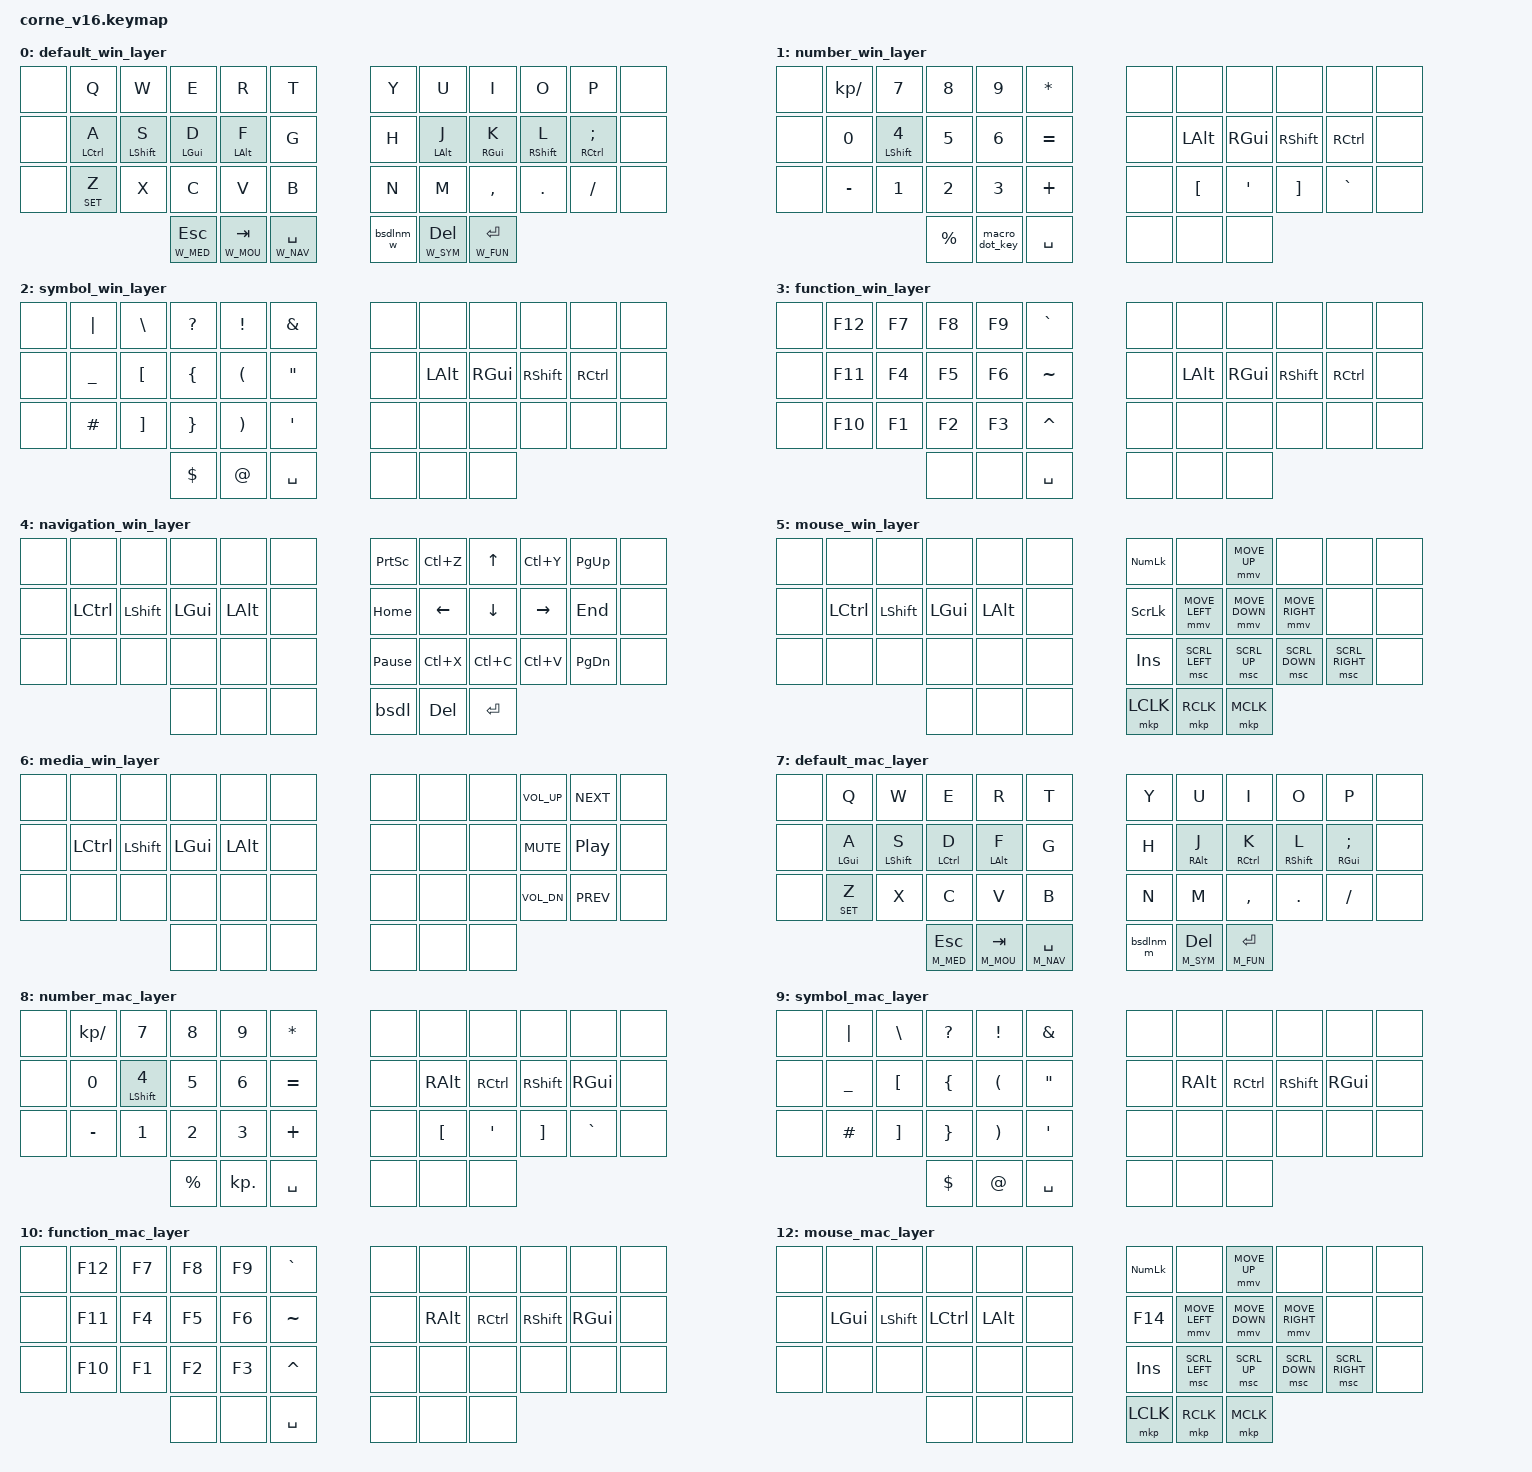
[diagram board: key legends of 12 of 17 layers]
#include <behaviors.dtsi>
#include <dt-bindings/zmk/keys.h>
#include <dt-bindings/zmk/bt.h>
#include <dt-bindings/zmk/outputs.h>
#include <dt-bindings/zmk/mouse.h>

#define W_DEF     0
#define W_NUM     1
#define W_SYM     2
#define W_FUN     3
#define W_NAV     4
#define W_MOU     5
#define W_MED     6

#define M_DEF     7
#define M_NUM     8
#define M_SYM     9
#define M_FUN     10
#define M_NAV     11
#define M_MOU     12
#define M_MED     13

#define CS1       14
#define CS2       15

#define SET       16

&lt {
	flavor = "hold-preferred";
	tapping-term-ms = <300>;
	quick-tap-ms = <300>;
	// global-quick-tap;
};

/ {
	behaviors {
		ht: hold_tap_kp_kp {
			label = "hold_tap";
			compatible = "zmk,behavior-hold-tap";
			#binding-cells = <2>;
			flavor = "balanced";
			// flavor = "hold-preferred";
			tapping-term-ms = <250>;
			quick-tap-ms = <250>;
			// global-quick-tap;
			bindings = <&kp>, <&kp>;
		};
		bsdl: bcksp_del {
            		compatible = "zmk,behavior-mod-morph";
            		#binding-cells = <0>;
            		bindings = <&kp BSPC>, <&kp DEL>;
            		mods = <(MOD_LSFT|MOD_RSFT)>;
        	};
		bsdlnm_w: bcksp_del_num_w {
            		compatible = "zmk,behavior-mod-morph";
            		#binding-cells = <0>;
            		bindings = <&lt W_NUM BSPC>, <&lt W_NUM DEL>;
            		mods = <(MOD_LSFT|MOD_RSFT)>;
        	};
		bsdlnm_m: bcksp_del_num_m {
            		compatible = "zmk,behavior-mod-morph";
            		#binding-cells = <0>;
            		bindings = <&lt M_NUM BSPC>, <&lt M_NUM DEL>;
            		mods = <(MOD_LSFT|MOD_RSFT)>;
        	};	};

	macros {
		macro_dot_key: macro_dot_key {
			compatible = "zmk,behavior-macro";
			#binding-cells = <0>;
			wait-ms = <40>;
			tap-ms = <40>;
			bindings
				= <&kp KP_NUM>
				, <&kp KP_DOT>
				, <&kp CLEAR2>
				;
		};
	};

        keymap {
                compatible = "zmk,keymap";

                default_win_layer {
                        bindings = <
//╭───────┬───────────────┬───────────────┬───────────────┬───────────────┬───────────────╮   ╭───────────────┬───────────────┬───────────────┬───────────────┬───────────────┬───────╮
//│       │ Q             │ W             │ E             │ R             │ T             │   │ Y             │ U             │ I             │ O             │ P             │       │
    &none   &kp Q           &kp W           &kp E           &kp R           &kp T               &kp Y           &kp U           &kp I           &kp O           &kp P           &none
//├───────┼───────────────┼───────────────┼───────────────┼───────────────┼───────────────┤   ├───────────────┼───────────────┼───────────────┼───────────────┼───────────────┼───────┤
//│       │ A(CTRL)       │ S(SHIFT)      │ D(GUI)        │ F(ALT)        │ G             │   │ H             │ J(ALT)        │ K(GUI)        │ L(SHIFT)      │ ;(CTRL)       │       │
    &none   &ht LCTRL A     &ht LSHFT S     &ht LGUI D      &ht LALT F      &kp G               &kp H           &ht LALT J      &ht RGUI K      &ht RSHFT L     &ht RCTRL SEMI  &none
//├───────┼───────────────┼───────────────┼───────────────┼───────────────┼───────────────┤   ├───────────────┼───────────────┼───────────────┼───────────────┼───────────────┼───────┤
//│       │ Z(MO SET)     │ X             │ C             │ V             │ B             │   │ N             │ M             │ ,             │ .             │ /             │       │
    &none   &lt SET Z       &kp X           &kp C           &kp V           &kp B               &kp N           &kp M           &kp COMMA       &kp DOT         &kp FSLH        &none
//╰───────┴───────────────┴───────────────┼───────────────┼───────────────┼───────────────┤   ├───────────────┼───────────────┼───────────────┼───────────────┴───────────────┴───────╯
//                                        │ ESC(MO MED)   │ TAB(MO MOU)   │ SPACE(MO NAV) │   │ BKSPDL(MO NUM)│ DEL(MO SYM)   │ ENTER(MO FUN) │
                                            &lt W_MED ESC   &lt W_MOU TAB   &lt W_NAV SPACE     &bsdlnm_w       &lt W_SYM DEL   &lt W_FUN RET
//                                        ╰───────────────┴───────────────┴───────────────╯   ╰───────────────┴───────────────┴───────────────╯
                        >;
                };
                number_win_layer {
                        bindings = <
//╭───────┬───────────────┬───────────────┬───────────────┬───────────────┬───────────────╮   ╭───────────────┬───────────────┬───────────────┬───────────────┬───────────────┬───────╮
//│       │ /             │ 7             │ 8             │ 9             │ *             │   │               │               │               │               │               │       │
    &none   &kp KP_DIVIDE   &kp N7          &kp N8          &kp N9          &kp STAR            &none           &none           &none           &none           &none           &none
//├───────┼───────────────┼───────────────┼───────────────┼───────────────┼───────────────┤   ├───────────────┼───────────────┼───────────────┼───────────────┼───────────────┼───────┤
//│       │ 0             │ 4(SHIFT)      │ 5             │ 6             │ =             │   │               │ ALT           │ GUI           │ SHIFT         │ CTRL          │       │
    &none   &kp N0          &ht LSHFT N4    &kp N5          &kp N6          &kp EQUAL           &none           &kp LALT        &kp RGUI        &kp RSHFT       &kp RCTRL       &none
//├───────┼───────────────┼───────────────┼───────────────┼───────────────┼───────────────┤   ├───────────────┼───────────────┼───────────────┼───────────────┼───────────────┼───────┤
//│       │ -             │ 1             │ 2             │ 3             │ +             │   │               │ Х             │ Э             │ Ъ             │ Ё             │       │
    &none   &kp MINUS       &kp N1          &kp N2          &kp N3          &kp PLUS            &none           &kp LBKT        &kp SQT         &kp RBKT        &kp GRAVE       &none
//╰───────┴───────────────┴───────────────┼───────────────┼───────────────┼───────────────┤   ├───────────────┼───────────────┼───────────────┼───────────────┴───────────────┴───────╯
//                                        │ %             │ .             │ SPACE         │   │               │               │               │
                                            &kp PRCNT       &macro_dot_key  &kp SPACE           &none           &none           &none
//                                        ╰───────────────┴───────────────┴───────────────╯   ╰───────────────┴───────────────┴───────────────╯
                        >;
                };
                symbol_win_layer {
                        bindings = <
//╭───────┬───────────────┬───────────────┬───────────────┬───────────────┬───────────────╮   ╭───────────────┬───────────────┬───────────────┬───────────────┬───────────────┬───────╮
//│       │ |             │ \             │ ?             │ !             │ &             │   │               │               │               │               │               │       │
    &none   &kp PIPE        &kp BSLH        &kp QMARK       &kp EXCL        &kp AMPS            &none           &none           &none           &none           &none           &none
//├───────┼───────────────┼───────────────┼───────────────┼───────────────┼───────────────┤   ├───────────────┼───────────────┼───────────────┼───────────────┼───────────────┼───────┤
//│       │ _             │ [             │ {             │ (             │ "             │   │               │ ALT           │ GUI           │ SHIFT         │ CTRL          │       │
    &none   &kp UNDER       &kp LBKT        &kp LBRC        &kp LPAR        &kp DQT             &none           &kp LALT        &kp RGUI        &kp RSHFT       &kp RCTRL       &none
//├───────┼───────────────┼───────────────┼───────────────┼───────────────┼───────────────┤   ├───────────────┼───────────────┼───────────────┼───────────────┼───────────────┼───────┤
//│       │ #             │ ]             │ }             │ )             │ '             │   │               │               │               │               │               │       │
    &none   &kp HASH        &kp RBKT        &kp RBRC        &kp RPAR        &kp SQT             &none           &none           &none           &none           &none           &none
//╰───────┴───────────────┴───────────────┼───────────────┼───────────────┼───────────────┤   ├───────────────┼───────────────┼───────────────┼───────────────┴───────────────┴───────╯
//                                        │ $             │ @             │ SPACE         │   │               │               │               │
                                            &kp DLLR        &kp AT          &kp SPACE           &none           &none           &none
//                                        ╰───────────────┴───────────────┴───────────────╯   ╰───────────────┴───────────────┴───────────────╯
                        >;
                };
                function_win_layer {
                        bindings = <
//╭───────┬───────────────┬───────────────┬───────────────┬───────────────┬───────────────╮   ╭───────────────┬───────────────┬───────────────┬───────────────┬───────────────┬───────╮
//│       │ F12           │ F7            │ F8            │ F9            │ `             │   │               │               │               │               │               │       │
    &none   &kp F12         &kp F7          &kp F8          &kp F9          &kp GRAVE           &none           &none           &none           &none           &none           &none
//├───────┼───────────────┼───────────────┼───────────────┼───────────────┼───────────────┤   ├───────────────┼───────────────┼───────────────┼───────────────┼───────────────┼───────┤
//│       │ F11           │ F4            │ F5            │ F6            │ ~             │   │               │ ALT           │ GUI           │ SHIFT         │ CTRL          │       │
    &none   &kp F11         &kp F4          &kp F5          &kp F6          &kp TILDE           &none           &kp LALT        &kp RGUI        &kp RSHFT       &kp RCTRL       &none
//├───────┼───────────────┼───────────────┼───────────────┼───────────────┼───────────────┤   ├───────────────┼───────────────┼───────────────┼───────────────┼───────────────┼───────┤
//│       │ F10           │ F1            │ F2            │ F3            │ ^             │   │               │               │               │               │               │       │
    &none   &kp F10         &kp F1          &kp F2          &kp F3          &kp CARET           &none           &none           &none           &none           &none           &none
//╰───────┴───────────────┴───────────────┼───────────────┼───────────────┼───────────────┤   ├───────────────┼───────────────┼───────────────┼───────────────┴───────────────┴───────╯
//                                        │               │               │ SPACE         │   │               │               │               │   
                                            &none           &none           &kp SPACE           &none           &none           &none
//                                        ╰───────────────┴───────────────┴───────────────╯   ╰───────────────┴───────────────┴───────────────╯
                        >;
                };
                navigation_win_layer {
                        bindings = <
//╭───────┬───────────────┬───────────────┬───────────────┬───────────────┬───────────────╮   ╭───────────────┬───────────────┬───────────────┬───────────────┬───────────────┬───────╮
//│       │               │               │               │               │               │   │ PrtScr        │ Undo          │ Up            │ Redo          │ PGUP          │       │
    &none   &none           &none           &none           &none           &none               &kp PSCRN       &kp LC(Z)       &kp UP          &kp LC(Y)       &kp PG_UP       &none
//├───────┼───────────────┼───────────────┼───────────────┼───────────────┼───────────────┤   ├───────────────┼───────────────┼───────────────┼───────────────┼───────────────┼───────┤
//│       │ CTRL          │ SHIFT         │ GUI           │ ALT           │               │   │ HOME          │ Left          │ Down          │ Right         │ END           │       │
    &none   &kp LCTRL       &kp LSHFT       &kp LGUI        &kp LALT        &none               &kp HOME        &kp LEFT        &kp DOWN        &kp RIGHT       &kp END         &none
//├───────┼───────────────┼───────────────┼───────────────┼───────────────┼───────────────┤   ├───────────────┼───────────────┼───────────────┼───────────────┼───────────────┼───────┤
//│       │               │               │               │               │               │   │ Pause         │ Cut           │ Copy          │ Paste         │ PGDN          │       │
    &none   &none           &none           &none           &none           &none               &kp PAUSE_BREAK &kp LC(X)       &kp LC(C)       &kp LC(V)       &kp PG_DN       &none
//╰───────┴───────────────┴───────────────┼───────────────┼───────────────┼───────────────┤   ├───────────────┼───────────────┼───────────────┼───────────────┴───────────────┴───────╯
//                                        │               │               │               │   │ BKSP_DEL      │ DEL           │ ENTER         │
                                            &none           &none           &none               &bsdl           &kp DEL         &kp RET
//                                        ╰───────────────┴───────────────┴───────────────╯   ╰───────────────┴───────────────┴───────────────╯
                        >;
                };
                mouse_win_layer {
                        bindings = <
//╭───────┬───────────────┬───────────────┬───────────────┬───────────────┬───────────────╮   ╭───────────────┬───────────────┬───────────────┬───────────────┬───────────────┬───────╮
//│       │               │               │               │               │               │   │ NumLock       │               │ MS Up         │               │               │       │
    &none   &none           &none           &none           &none           &none               &kp KP_NUM      &none           &mmv MOVE_UP    &none           &none           &none
//├───────┼───────────────┼───────────────┼───────────────┼───────────────┼───────────────┤   ├───────────────┼───────────────┼───────────────┼───────────────┼───────────────┼───────┤
//│       │ CTRL          │ SHIFT         │ GUI           │ ALT           │               │   │ ScrLock       │ MS Left       │ MS Down       │ MS Right      │               │       │
    &none   &kp LCTRL       &kp LSHFT       &kp LGUI        &kp LALT        &none               &kp SLCK        &mmv MOVE_LEFT  &mmv MOVE_DOWN &mmv MOVE_RIGHT  &none           &none
//├───────┼───────────────┼───────────────┼───────────────┼───────────────┼───────────────┤   ├───────────────┼───────────────┼───────────────┼───────────────┼───────────────┼───────┤
//│       │               │               │               │               │               │   │ Insert        │ SC Left       │ SC Up         │ SC Down       │ SC Right      │       │
    &none   &none           &none           &none           &none           &none               &kp INS         &msc SCRL_LEFT  &msc SCRL_UP    &msc SCRL_DOWN  &msc SCRL_RIGHT &none
//╰───────┴───────────────┴───────────────┼───────────────┼───────────────┼───────────────┤   ├───────────────┼───────────────┼───────────────┼───────────────┴───────────────┴───────╯
//                                        │               │               │               │   │ MS_BT_Left    │ MS_BT_Right   │ MS_BT_Middle  │
                                            &none           &none           &none               &mkp LCLK       &mkp RCLK       &mkp MCLK
//                                        ╰───────────────┴───────────────┴───────────────╯   ╰───────────────┴───────────────┴───────────────╯
                        >;
                };
                media_win_layer {
                        bindings = <
//╭───────┬───────────────┬───────────────┬───────────────┬───────────────┬───────────────╮   ╭───────────────┬───────────────┬───────────────┬───────────────┬───────────────┬───────╮
//│       │               │               │               │               │               │   │               │               │               │ Volume Up     │ Skip Forward  │       │
    &none   &none           &none           &none           &none           &none               &none           &none           &none           &kp C_VOL_UP    &kp C_NEXT      &none
//├───────┼───────────────┼───────────────┼───────────────┼───────────────┼───────────────┤   ├───────────────┼───────────────┼───────────────┼───────────────┼───────────────┼───────┤
//│       │ CTRL          │ SHIFT         │ GUI           │ ALT           │               │   │               │               │               │ Mute          │ Play Paus     │       │
    &none   &kp LCTRL       &kp LSHFT       &kp LGUI        &kp LALT        &none               &none           &none           &none           &kp C_MUTE      &kp C_PP        &none
//├───────┼───────────────┼───────────────┼───────────────┼───────────────┼───────────────┤   ├───────────────┼───────────────┼───────────────┼───────────────┼───────────────┼───────┤
//│       │               │               │               │               │               │   │               │               │               │ Volume Down   │ Skip Back     │       │
    &none   &none           &none           &none           &none           &none               &none           &none           &none           &kp C_VOL_DN    &kp C_PREV      &none
//╰───────┴───────────────┴───────────────┼───────────────┼───────────────┼───────────────┤   ├───────────────┼───────────────┼───────────────┼───────────────┴───────────────┴───────╯
//                                        │               │               │               │   │               │               │               │
                                            &none           &none           &none               &none           &none           &none
//                                        ╰───────────────┴───────────────┴───────────────╯   ╰───────────────┴───────────────┴───────────────╯
                        >;
                };
		default_mac_layer {
                        bindings = <
//╭───────┬───────────────┬───────────────┬───────────────┬───────────────┬───────────────╮   ╭───────────────┬───────────────┬───────────────┬───────────────┬───────────────┬───────╮
//│       │ Q             │ W             │ E             │ R             │ T             │   │ Y             │ U             │ I             │ O             │ P             │       │
    &none   &kp Q           &kp W           &kp E           &kp R           &kp T               &kp Y           &kp U           &kp I           &kp O           &kp P           &none
//├───────┼───────────────┼───────────────┼───────────────┼───────────────┼───────────────┤   ├───────────────┼───────────────┼───────────────┼───────────────┼───────────────┼───────┤
//│       │ A(GUI)        │ S(SHIFT)      │ D(CTRL)       │ F(ALT)        │ G             │   │ H             │ J(ALT)        │ K(CTRL)       │ L(SHIFT)      │ ;(GUI)        │       │
    &none   &ht LGUI A      &ht LSHFT S     &ht LCTRL D     &ht LALT F      &kp G               &kp H           &ht RALT J      &ht RCTRL K     &ht RSHFT L     &ht RGUI SEMI   &none
//├───────┼───────────────┼───────────────┼───────────────┼───────────────┼───────────────┤   ├───────────────┼───────────────┼───────────────┼───────────────┼───────────────┼───────┤
//│       │ Z(MO SET)     │ X             │ C             │ V             │ B             │   │ N             │ M             │ ,             │ .             │ /             │       │
    &none   &lt SET Z       &kp X           &kp C           &kp V           &kp B               &kp N           &kp M           &kp COMMA       &kp DOT         &kp FSLH        &none
//╰───────┴───────────────┴───────────────┼───────────────┼───────────────┼───────────────┤   ├───────────────┼───────────────┼───────────────┼───────────────┴───────────────┴───────╯
//                                        │ ESC(MO MED)   │ TAB(MO MOU)   │ SPACE(MO NAV) │   │ BKSPDL(MO NUM)│ DEL(MO SYM)   │ ENTER(MO FUN) │
                                            &lt M_MED ESC   &lt M_MOU TAB   &lt M_NAV SPACE     &bsdlnm_m       &lt M_SYM DEL   &lt M_FUN RET
//                                        ╰───────────────┴───────────────┴───────────────╯   ╰───────────────┴───────────────┴───────────────╯
                        >;
                };
                number_mac_layer {
                        bindings = <
//╭───────┬───────────────┬───────────────┬───────────────┬───────────────┬───────────────╮   ╭───────────────┬───────────────┬───────────────┬───────────────┬───────────────┬───────╮
//│       │ +             │ 7             │ 8             │ 9             │ *             │   │               │               │               │               │               │       │
    &none   &kp KP_DIVIDE   &kp N7          &kp N8          &kp N9          &kp STAR            &none           &none           &none           &none           &none           &none
//├───────┼───────────────┼───────────────┼───────────────┼───────────────┼───────────────┤   ├───────────────┼───────────────┼───────────────┼───────────────┼───────────────┼───────┤
//│       │ 0             │ 4(SHIFT)      │ 5             │ 6             │ =             │   │               │ ALT           │ CTRL          │ SHIFT         │ GUI           │       │
    &none   &kp N0          &ht LSHFT N4    &kp N5          &kp N6          &kp EQUAL           &none           &kp RALT        &kp RCTRL       &kp RSHFT       &kp RGUI        &none
//├───────┼───────────────┼───────────────┼───────────────┼───────────────┼───────────────┤   ├───────────────┼───────────────┼───────────────┼───────────────┼───────────────┼───────┤
//│       │ -             │ 1             │ 2             │ 3             │ /             │   │               │ Х             │ Э             │ Ъ             │ Ё             │       │
    &none   &kp MINUS       &kp N1          &kp N2          &kp N3          &kp PLUS            &none           &kp LBKT        &kp SQT         &kp RBKT        &kp GRAVE       &none
//╰───────┴───────────────┴───────────────┼───────────────┼───────────────┼───────────────┤   ├───────────────┼───────────────┼───────────────┼───────────────┴───────────────┴───────╯
//                                        │ %             │ .             │ SPACE         │   │               │               │               │
                                            &kp PRCNT       &kp KP_DOT      &kp SPACE           &none           &none           &none
//                                        ╰───────────────┴───────────────┴───────────────╯   ╰───────────────┴───────────────┴───────────────╯
                        >;
                };
                symbol_mac_layer {
                        bindings = <
//╭───────┬───────────────┬───────────────┬───────────────┬───────────────┬───────────────╮   ╭───────────────┬───────────────┬───────────────┬───────────────┬───────────────┬───────╮
//│       │ |             │ \             │ ?             │ !             │ &             │   │               │               │               │               │               │       │
    &none   &kp PIPE        &kp BSLH        &kp QMARK       &kp EXCL        &kp AMPS            &none           &none           &none           &none           &none           &none
//├───────┼───────────────┼───────────────┼───────────────┼───────────────┼───────────────┤   ├───────────────┼───────────────┼───────────────┼───────────────┼───────────────┼───────┤
//│       │ _             │ [             │ {             │ (             │ "             │   │               │ ALT           │ CTRL          │ SHIFT         │ GUI           │       │
    &none   &kp UNDER       &kp LBKT        &kp LBRC        &kp LPAR        &kp DQT             &none           &kp RALT        &kp RCTRL       &kp RSHFT       &kp RGUI        &none
//├───────┼───────────────┼───────────────┼───────────────┼───────────────┼───────────────┤   ├───────────────┼───────────────┼───────────────┼───────────────┼───────────────┼───────┤
//│       │ #             │ ]             │ }             │ )             │ '             │   │               │               │               │               │               │       │
    &none   &kp HASH        &kp RBKT        &kp RBRC        &kp RPAR        &kp SQT             &none           &none           &none           &none           &none           &none
//╰───────┴───────────────┴───────────────┼───────────────┼───────────────┼───────────────┤   ├───────────────┼───────────────┼───────────────┼───────────────┴───────────────┴───────╯
//                                        │ $             │ @             │ SPACE         │   │               │               │               │
                                            &kp DLLR        &kp AT          &kp SPACE           &none           &none           &none
//                                        ╰───────────────┴───────────────┴───────────────╯   ╰───────────────┴───────────────┴───────────────╯
                        >;
                };
                function_mac_layer {
                        bindings = <
//╭───────┬───────────────┬───────────────┬───────────────┬───────────────┬───────────────╮   ╭───────────────┬───────────────┬───────────────┬───────────────┬───────────────┬───────╮
//│       │ F12           │ F7            │ F8            │ F9            │ `             │   │               │               │               │               │               │       │
    &none   &kp F12         &kp F7          &kp F8          &kp F9          &kp GRAVE           &none           &none           &none           &none           &none           &none
//├───────┼───────────────┼───────────────┼───────────────┼───────────────┼───────────────┤   ├───────────────┼───────────────┼───────────────┼───────────────┼───────────────┼───────┤
//│       │ F11           │ F4            │ F5            │ F6            │ ~             │   │               │ ALT           │ CTRL          │ SHIFT         │ GUI           │       │
    &none   &kp F11         &kp F4          &kp F5          &kp F6          &kp TILDE           &none           &kp RALT        &kp RCTRL       &kp RSHFT       &kp RGUI        &none
//├───────┼───────────────┼───────────────┼───────────────┼───────────────┼───────────────┤   ├───────────────┼───────────────┼───────────────┼───────────────┼───────────────┼───────┤
//│       │ F10           │ F1            │ F2            │ F3            │ ^             │   │               │               │               │               │               │       │
    &none   &kp F10         &kp F1          &kp F2          &kp F3          &kp CARET           &none           &none           &none           &none           &none           &none
//╰───────┴───────────────┴───────────────┼───────────────┼───────────────┼───────────────┤   ├───────────────┼───────────────┼───────────────┼───────────────┴───────────────┴───────╯
//                                        │               │               │ SPACE         │   │               │               │               │   
                                            &none           &none           &kp SPACE           &none           &none           &none
//                                        ╰───────────────┴───────────────┴───────────────╯   ╰───────────────┴───────────────┴───────────────╯
                        >;
                };
                navigation_mac_layer {
                        bindings = <
//╭───────┬───────────────┬───────────────┬───────────────┬───────────────┬───────────────╮   ╭───────────────┬───────────────┬───────────────┬───────────────┬───────────────┬───────╮
//│       │               │               │               │               │               │   │ PrtScr        │ Undo          │ Up            │ Redo          │ PGUP          │       │
    &none   &none           &none           &none           &none           &none            &kp LG(LS(LC(N3))) &kp LG(Z)       &kp UP          &kp LS(LG(Z))   &kp PG_UP       &none
//├───────┼───────────────┼───────────────┼───────────────┼───────────────┼───────────────┤   ├───────────────┼───────────────┼───────────────┼───────────────┼───────────────┼───────┤
//│       │ GUI           │ SHIFT         │ CTRL          │ ALT           │               │   │ HOME          │ Left          │ Down          │ Right         │ END           │       │
    &none   &kp LGUI        &kp LSHFT       &kp LCTRL       &kp LALT        &none               &kp HOME        &kp LEFT        &kp DOWN        &kp RIGHT       &kp END         &none
//├───────┼───────────────┼───────────────┼───────────────┼───────────────┼───────────────┤   ├───────────────┼───────────────┼───────────────┼───────────────┼───────────────┼───────┤
//│       │               │               │               │               │               │   │ Pause (F15)   │ Cut           │ Copy          │ Paste         │ PGDN          │       │
    &none   &none           &none           &none           &none           &none               &kp F15         &kp LG(X)       &kp LG(C)       &kp LG(V)       &kp PG_DN       &none
//╰───────┴───────────────┴───────────────┼───────────────┼───────────────┼───────────────┤   ├───────────────┼───────────────┼───────────────┼───────────────┴───────────────┴───────╯
//                                        │               │               │               │   │ BKSP_DEL      │ DEL           │ ENTER         │
                                            &none           &none           &none               &bsdl           &kp DEL         &kp RET
//                                        ╰───────────────┴───────────────┴───────────────╯   ╰───────────────┴───────────────┴───────────────╯
                        >;
                };
                mouse_mac_layer {
                        bindings = <
//╭───────┬───────────────┬───────────────┬───────────────┬───────────────┬───────────────╮   ╭───────────────┬───────────────┬───────────────┬───────────────┬───────────────┬───────╮
//│       │               │               │               │               │               │   │ NumLock       │               │ MS Up         │               │               │       │
    &none   &none           &none           &none           &none           &none               &kp KP_NUM      &none           &mmv MOVE_UP    &none           &none           &none
//├───────┼───────────────┼───────────────┼───────────────┼───────────────┼───────────────┤   ├───────────────┼───────────────┼───────────────┼───────────────┼───────────────┼───────┤
//│       │ GUI           │ SHIFT         │ CTRL          │ ALT           │               │   │ ScrLock (F14) │ MS Left       │ MS Down       │ MS Right      │               │       │
    &none   &kp LGUI        &kp LSHFT       &kp LCTRL       &kp LALT        &none               &kp F14         &mmv MOVE_LEFT  &mmv MOVE_DOWN &mmv MOVE_RIGHT  &none           &none
//├───────┼───────────────┼───────────────┼───────────────┼───────────────┼───────────────┤   ├───────────────┼───────────────┼───────────────┼───────────────┼───────────────┼───────┤
//│       │               │               │               │               │               │   │ Insert        │ SC Left       │ SC Up         │ SC Down       │ SC Right      │       │
    &none   &none           &none           &none           &none           &none               &kp INS         &msc SCRL_LEFT  &msc SCRL_UP    &msc SCRL_DOWN  &msc SCRL_RIGHT &none
//╰───────┴───────────────┴───────────────┼───────────────┼───────────────┼───────────────┤   ├───────────────┼───────────────┼───────────────┼───────────────┴───────────────┴───────╯
//                                        │               │               │               │   │ MS_BT_Left    │ MS_BT_Right   │ MS_BT_Middle  │
                                            &none           &none           &none               &mkp LCLK       &mkp RCLK       &mkp MCLK
//                                        ╰───────────────┴───────────────┴───────────────╯   ╰───────────────┴───────────────┴───────────────╯
                        >;
                };
                media_mac_layer {
                        bindings = <
//╭───────┬───────────────┬───────────────┬───────────────┬───────────────┬───────────────╮   ╭───────────────┬───────────────┬───────────────┬───────────────┬───────────────┬───────╮
//│       │               │               │               │               │               │   │               │               │               │ Volume Up     │ Skip Forward  │       │
    &none   &none           &none           &none           &none           &none               &none           &none           &none           &kp C_VOL_UP    &kp C_NEXT      &none
//├───────┼───────────────┼───────────────┼───────────────┼───────────────┼───────────────┤   ├───────────────┼───────────────┼───────────────┼───────────────┼───────────────┼───────┤
//│       │ GUI           │ SHIFT         │ CTRL          │ ALT           │               │   │               │               │               │ Mute          │ Play Paus     │       │
    &none   &kp LGUI        &kp LSHFT       &kp LCTRL       &kp LALT        &none               &none           &none           &none           &kp C_MUTE      &kp C_PP        &none
//├───────┼───────────────┼───────────────┼───────────────┼───────────────┼───────────────┤   ├───────────────┼───────────────┼───────────────┼───────────────┼───────────────┼───────┤
//│       │               │               │               │               │               │   │               │               │               │ Volume Down   │ Skip Back     │       │
    &none   &none           &none           &none           &none           &none               &none           &none           &none           &kp C_VOL_DN    &kp C_PREV      &none
//╰───────┴───────────────┴───────────────┼───────────────┼───────────────┼───────────────┤   ├───────────────┼───────────────┼───────────────┼───────────────┴───────────────┴───────╯
//                                        │               │               │               │   │               │               │               │
                                            &none           &none           &none               &none           &none           &none
//                                        ╰───────────────┴───────────────┴───────────────╯   ╰───────────────┴───────────────┴───────────────╯
                        >;
                };
                cs1_layer {
                        bindings = <
//╭───────┬───────────────┬───────────────┬───────────────┬───────────────┬───────────────╮   ╭───────────────┬───────────────┬───────────────┬───────────────┬───────────────┬───────╮
//│       │ ESC           │ 1             │ W             │ 2             │ R             │   │               │               │               │               │               │       │
    &none   &kp ESC         &kp N1          &kp W           &kp N2          &kp R               &none           &none           &none           &none           &none           &none
//├───────┼───────────────┼───────────────┼───────────────┼───────────────┼───────────────┤   ├───────────────┼───────────────┼───────────────┼───────────────┼───────────────┼───────┤
//│       │ SHIFT         │ A             │ S             │ D             │ E             │   │               │               │               │               │               │       │
    &none   &kp LSHFT       &kp A           &kp S           &kp D           &kp E               &none           &none           &none           &none           &none           &none
//├───────┼───────────────┼───────────────┼───────────────┼───────────────┼───────────────┤   ├───────────────┼───────────────┼───────────────┼───────────────┼───────────────┼───────┤
//│       │ CTRL          │ 3             │ 4             │ 5             │ B             │   │               │               │               │               │               │       │
    &none   &kp LCTRL       &kp N3          &kp N4          &kp N5          &kp B               &none           &none           &none           &none           &none           &none
//╰───────┴───────────────┴───────────────┼───────────────┼───────────────┼───────────────┤   ├───────────────┼───────────────┼───────────────┼───────────────┴───────────────┴───────╯
//                                        │ K             │ TAB (MO CS2)  │ SPACE         │   │               │               │               │
                                            &kp K           &lt CS2 TAB     &kp SPACE           &none           &none           &none
//                                        ╰───────────────┴───────────────┴───────────────╯   ╰───────────────┴───────────────┴───────────────╯
                        >;
                };
                cs2_layer {
                        bindings = <
//╭───────┬───────────────┬───────────────┬───────────────┬───────────────┬───────────────╮   ╭───────────────┬───────────────┬───────────────┬───────────────┬───────────────┬───────╮
//│       │ 6             │ 7             │               │ 8             │ 0             │   │               │               │               │               │               │       │
    &none   &kp N6          &kp N7          &trans          &kp N8          &kp N0              &none           &none           &none           &none           &none           &none
//├───────┼───────────────┼───────────────┼───────────────┼───────────────┼───────────────┤   ├───────────────┼───────────────┼───────────────┼───────────────┼───────────────┼───────┤
//│       │               │               │               │               │ G             │   │               │               │               │               │               │       │
    &none   &trans          &trans          &trans          &trans          &kp G               &none           &none           &none           &none           &none           &none
//├───────┼───────────────┼───────────────┼───────────────┼───────────────┼───────────────┤   ├───────────────┼───────────────┼───────────────┼───────────────┼───────────────┼───────┤
//│       │               │ F1            │ F2            │ F3            │ F4            │   │               │               │               │               │               │       │
    &none   &mo SET         &kp F1          &kp F2          &kp F3          &kp F4              &none           &none           &none           &none           &none           &none
//╰───────┴───────────────┴───────────────┼───────────────┼───────────────┼───────────────┤   ├───────────────┼───────────────┼───────────────┼───────────────┴───────────────┴───────╯
//                                        │ F5            │               │ TAB           │   │               │               │               │
                                            &kp F5          &trans          &kp TAB             &none           &none           &none
//                                        ╰───────────────┴───────────────┴───────────────╯   ╰───────────────┴───────────────┴───────────────╯
                        >;
                };
                settings_layer {
                        bindings = <
//╭───────┬───────────────┬───────────────┬───────────────┬───────────────┬───────────────╮   ╭───────────────┬───────────────┬───────────────┬───────────────┬───────────────┬───────╮
//│       │ BTCLR         │ BT3           │ BT2           │ BT1           │ BT0           │   │               │               │               │               │               │       │
    &none   &bt BT_CLR      &bt BT_SEL 3    &bt BT_SEL 2    &bt BT_SEL 1    &bt BT_SEL 0        &none           &none           &none           &none           &none           &none
//├───────┼───────────────┼───────────────┼───────────────┼───────────────┼───────────────┤   ├───────────────┼───────────────┼───────────────┼───────────────┼───────────────┼───────┤
//│       │ OUT_TOG       │               │ TO MAC        │ TO WIN        │ TO CS1        │   │               │               │               │               │               │       │
    &none   &out OUT_TOG    &none           &to M_DEF       &to W_DEF       &to CS1             &none           &none           &none           &none           &none           &none
//├───────┼───────────────┼───────────────┼───────────────┼───────────────┼───────────────┤   ├───────────────┼───────────────┼───────────────┼───────────────┼───────────────┼───────┤
//│       │               │               │               │               │               │   │               │               │               │               │               │       │
    &none   &none           &none           &none           &none           &none               &none           &none           &none           &none           &none           &none
//╰───────┴───────────────┴───────────────┼───────────────┼───────────────┼───────────────┤   ├───────────────┼───────────────┼───────────────┼───────────────┴───────────────┴───────╯
//                                        │               │               │               │   │               │               │               │
                                            &none           &none           &none               &none           &none           &none
//                                        ╰───────────────┴───────────────┴───────────────╯   ╰───────────────┴───────────────┴───────────────╯
                        >;
                };
        };
};
